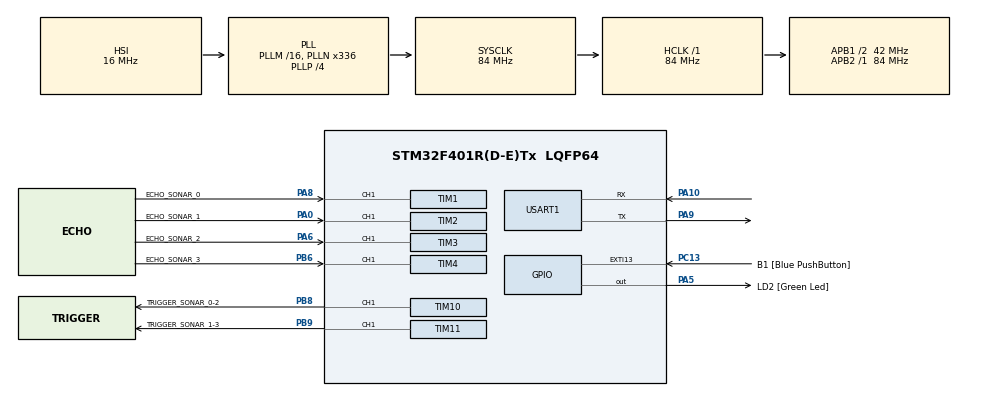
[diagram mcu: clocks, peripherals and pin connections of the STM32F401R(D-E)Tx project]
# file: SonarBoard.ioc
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Mcu.Family=STM32F4
Mcu.Name=STM32F401R(D-E)Tx
Mcu.Package=LQFP64
NVIC.PriorityGroup=NVIC_PRIORITYGROUP_4
NVIC.TIM1_CC_IRQn=true\:0\:0\:false
NVIC.TIM2_IRQn=true\:0\:0\:false
NVIC.TIM3_IRQn=true\:0\:0\:false
NVIC.TIM4_IRQn=true\:0\:0\:false
NVIC.TIM5_IRQn=true\:0\:0\:false
NVIC.USART1_IRQn=true\:0\:0\:false
PA0-WKUP.GPIO_Label=ECHO_SONAR_1
PA0-WKUP.Signal=S_TIM2_CH1_ETR
PA10.Mode=Asynchronous
PA10.Signal=USART1_RX
PA13.GPIO_Label=TMS
PA13.Mode=Trace-Asynchronous_SW
PA13.Signal=SYS_JTMS-SWDIO
PA14.GPIO_Label=TCK
PA14.Mode=Trace-Asynchronous_SW
PA14.Signal=SYS_JTCK-SWCLK
PA2.GPIO_Label=USART_TX
PA2.GPIO_Mode=GPIO_MODE_AF_PP
PA2.GPIO_PuPd=GPIO_NOPULL
PA2.GPIO_Speed=GPIO_SPEED_LOW
PA2.Signal=USART2_TX
PA3.GPIO_Label=USART_RX
PA3.GPIO_Mode=GPIO_MODE_AF_PP
PA3.GPIO_PuPd=GPIO_NOPULL
PA3.GPIO_Speed=GPIO_SPEED_LOW
PA3.Signal=USART2_RX
PA5.GPIO_Label=LD2 [Green Led]
PA5.GPIO_Mode=GPIO_MODE_OUTPUT_PP
PA5.GPIO_PuPd=GPIO_NOPULL
PA5.GPIO_Speed=GPIO_SPEED_LOW
PA5.Signal=GPIO_Output
PA6.GPIO_Label=ECHO_SONAR_2
PA6.Signal=S_TIM3_CH1
PA8.GPIO_Label=ECHO_SONAR_0
PA8.Signal=S_TIM1_CH1
PA9.Mode=Asynchronous
PA9.Signal=USART1_TX
PB3.GPIO_Label=SWO
PB3.Mode=Trace-Asynchronous_SW
PB3.Signal=SYS_JTDO-SWO
PB6.GPIO_Label=ECHO_SONAR_3
PB6.Signal=S_TIM4_CH1
PB8.GPIO_Label=TRIGGER_SONAR_0-2
PB8.Signal=S_TIM10_CH1
PB9.GPIO_Label=TRIGGER_SONAR_1-3
PB9.Signal=S_TIM11_CH1
PC13-ANTI_TAMP.GPIO_Label=B1 [Blue PushButton]
PC13-ANTI_TAMP.GPIO_ModeDefaultEXTI=GPIO_MODE_EVT_RISING
PC13-ANTI_TAMP.GPIO_PuPd=GPIO_NOPULL
PC13-ANTI_TAMP.Signal=GPXTI13
PC14-OSC32_IN.Signal=RCC_OSC32_IN
PC15-OSC32_OUT.Signal=RCC_OSC32_OUT
PH0\ -\ OSC_IN.Signal=RCC_OSC_IN
PH1\ -\ OSC_OUT.Signal=RCC_OSC_OUT
ProjectManager.TargetToolchain=EWARM
RCC.AHBFreq_Value=84000000
RCC.APB1CLKDivider=RCC_HCLK_DIV2
RCC.APB1Freq_Value=42000000
RCC.APB1TimFreq_Value=84000000
RCC.APB2Freq_Value=84000000
RCC.APB2TimFreq_Value=84000000
RCC.CortexFreq_Value=84000000
RCC.HCLKFreq_Value=84000000
RCC.HSE_VALUE=8000000
RCC.HSI_VALUE=16000000
RCC.LSE_VALUE=32768
RCC.PLLN=336
RCC.PLLP=RCC_PLLP_DIV4
RCC.PLLQ=7
RCC.SYSCLKFreq_VALUE=84000000
RCC.SYSCLKSource=RCC_SYSCLKSOURCE_PLLCLK
RCC.VCOOutputFreq_Value=336000000
SH.S_TIM10_CH1.0=TIM10_CH1,PWM Generation1 CH1
SH.S_TIM11_CH1.0=TIM11_CH1,PWM Generation1 CH1
SH.S_TIM1_CH1.0=TIM1_CH1,TriggerSource_TI1FP1
SH.S_TIM1_CH1.1=TIM1_CH1,Input_Capture1_from_TI1
SH.S_TIM1_CH1.2=TIM1_CH1,Input_Capture2_from_TI1
SH.S_TIM2_CH1_ETR.0=TIM2_CH1,TriggerSource_TI1FP1
SH.S_TIM2_CH1_ETR.1=TIM2_CH1,Input_Capture1_from_TI1
SH.S_TIM2_CH1_ETR.2=TIM2_CH1,Input_Capture2_from_TI1
SH.S_TIM3_CH1.0=TIM3_CH1,TriggerSource_TI1FP1
SH.S_TIM3_CH1.1=TIM3_CH1,Input_Capture1_from_TI1
SH.S_TIM3_CH1.2=TIM3_CH1,Input_Capture2_from_TI1
SH.S_TIM4_CH1.0=TIM4_CH1,TriggerSource_TI1FP1
SH.S_TIM4_CH1.1=TIM4_CH1,Input_Capture1_from_TI1
SH.S_TIM4_CH1.2=TIM4_CH1,Input_Capture2_from_TI1
TIM1.Channel-Input_Capture2_from_TI1=TIM_CHANNEL_2
TIM1.ICPolarity_CH2=TIM_INPUTCHANNELPOLARITY_FALLING
TIM1.Period=65535
TIM1.Prescaler=83
TIM10.OCFastMode_PWM=TIM_OCFAST_ENABLE
TIM10.OCMode_PWM=TIM_OCMODE_PWM2
TIM10.Period=65535
TIM10.Prescaler=83
TIM10.Pulse=65526
TIM11.OCFastMode_PWM=TIM_OCFAST_ENABLE
TIM11.OCMode_PWM=TIM_OCMODE_PWM2
TIM11.Period=65535
TIM11.Prescaler=83
TIM11.Pulse=65526
TIM2.Channel-Input_Capture2_from_TI1=TIM_CHANNEL_2
TIM2.ICPolarity_CH2=TIM_INPUTCHANNELPOLARITY_FALLING
TIM2.Period=65535
TIM2.Prescaler=83
TIM3.Channel-Input_Capture2_from_TI1=TIM_CHANNEL_2
TIM3.ICPolarity_CH2=TIM_INPUTCHANNELPOLARITY_FALLING
TIM3.Period=65535
TIM3.Prescaler=83
TIM4.Channel-Input_Capture2_from_TI1=TIM_CHANNEL_2
TIM4.ICPolarity_CH2=TIM_INPUTCHANNELPOLARITY_FALLING
TIM4.Period=65535
TIM4.Prescaler=83
TIM5.Period=1000
TIM5.Prescaler=8400
VP_TIM10_VS_ClockSourceINT.Mode=Enable_Timer
VP_TIM10_VS_OPM.Mode=OPM_bit
VP_TIM11_VS_ClockSourceINT.Mode=Enable_Timer
VP_TIM11_VS_OPM.Mode=OPM_bit
VP_TIM1_VS_ClockSourceINT.Mode=Internal
VP_TIM1_VS_ControllerModeReset.Mode=Reset Mode
VP_TIM2_VS_ClockSourceINT.Mode=Internal
VP_TIM2_VS_ControllerModeReset.Mode=Reset Mode
VP_TIM3_VS_ClockSourceINT.Mode=Internal
VP_TIM3_VS_ControllerModeReset.Mode=Reset Mode
VP_TIM4_VS_ClockSourceINT.Mode=Internal
VP_TIM4_VS_ControllerModeReset.Mode=Reset Mode
VP_TIM5_VS_ClockSourceINT.Mode=Internal
board=NUCLEO-F401RE

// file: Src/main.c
/**
  ******************************************************************************
  * File Name          : main.c
  * Description        : Main program body
  ******************************************************************************
  *
  * COPYRIGHT(c) 2016 STMicroelectronics
  *
  * Redistribution and use in source and binary forms, with or without modification,
  * are permitted provided that the following conditions are met:
  *   1. Redistributions of source code must retain the above copyright notice,
  *      this list of conditions and the following disclaimer.
  *   2. Redistributions in binary form must reproduce the above copyright notice,
  *      this list of conditions and the following disclaimer in the documentation
  *      and/or other materials provided with the distribution.
  *   3. Neither the name of STMicroelectronics nor the names of its contributors
  *      may be used to endorse or promote products derived from this software
  *      without specific prior written permission.
  *
  * THIS SOFTWARE IS PROVIDED BY THE COPYRIGHT HOLDERS AND CONTRIBUTORS "AS IS"
  * AND ANY EXPRESS OR IMPLIED WARRANTIES, INCLUDING, BUT NOT LIMITED TO, THE
  * IMPLIED WARRANTIES OF MERCHANTABILITY AND FITNESS FOR A PARTICULAR PURPOSE ARE
  * DISCLAIMED. IN NO EVENT SHALL THE COPYRIGHT HOLDER OR CONTRIBUTORS BE LIABLE
  * FOR ANY DIRECT, INDIRECT, INCIDENTAL, SPECIAL, EXEMPLARY, OR CONSEQUENTIAL
  * DAMAGES (INCLUDING, BUT NOT LIMITED TO, PROCUREMENT OF SUBSTITUTE GOODS OR
  * SERVICES; LOSS OF USE, DATA, OR PROFITS; OR BUSINESS INTERRUPTION) HOWEVER
  * CAUSED AND ON ANY THEORY OF LIABILITY, WHETHER IN CONTRACT, STRICT LIABILITY,
  * OR TORT (INCLUDING NEGLIGENCE OR OTHERWISE) ARISING IN ANY WAY OUT OF THE USE
  * OF THIS SOFTWARE, EVEN IF ADVISED OF THE POSSIBILITY OF SUCH DAMAGE.
  *
  ******************************************************************************
  */
#include "stm32f4xx_hal.h"
#include "tim.h"
#include "usart.h"
#include "gpio.h"

/* USER CODE BEGIN Includes */
#include "sonar_handler.h"
#include "ser_handler.h"
#include "gpio.h"
/* USER CODE END Includes */

/* USER CODE BEGIN PV */
/* Private variables ---------------------------------------------------------*/

/* USER CODE END PV */

void SystemClock_Config(void);

/* USER CODE BEGIN PFP */
/* Private function prototypes -----------------------------------------------*/

/* USER CODE END PFP */

int main(void)
{

  /* USER CODE BEGIN 1 */f

  /* USER CODE END 1 */

  /* MCU Configuration----------------------------------------------------------*/

  /* Reset of all peripherals, Initializes the Flash interface and the Systick. */
  HAL_Init();

  /* Configure the system clock */
  SystemClock_Config();

  /* Initialize all configured peripherals */
  MX_GPIO_Init();
  MX_TIM1_Init();
  MX_TIM2_Init();
  MX_TIM3_Init();
  MX_TIM4_Init();
  MX_TIM5_Init();
  MX_TIM10_Init();
  MX_TIM11_Init();
  MX_USART1_UART_Init();

  /* USER CODE BEGIN 2 */
  HAL_TIM_Base_Start_IT( &htim5 ); // 100 msec timer
  initSonar( 4 );
  initSerOutput();
  /* USER CODE END 2 */

  /* Infinite loop */
  while (1)
  {

  /* USER CODE BEGIN 3 */
    // >>>>> Sonar reading
    triggerSonar( COUPLE_0_2 );
    HAL_Delay( 50 ); // 38 msec is the max echo duration
    triggerSonar( COUPLE_1_3 );
    HAL_Delay( 50 ); // 38 msec is the max echo duration
    // <<<<< Sonar reading

    // >>>>> Serial Output
    sendMeasures();
    // <<<<< Serial Output
  }
  /* USER CODE END 3 */

}

/** System Clock Configuration
*/
void SystemClock_Config(void)
{

  RCC_OscInitTypeDef RCC_OscInitStruct;
  RCC_ClkInitTypeDef RCC_ClkInitStruct;

  __PWR_CLK_ENABLE();

  __HAL_PWR_VOLTAGESCALING_CONFIG(PWR_REGULATOR_VOLTAGE_SCALE2);

  RCC_OscInitStruct.OscillatorType = RCC_OSCILLATORTYPE_HSI;
  RCC_OscInitStruct.HSIState = RCC_HSI_ON;
  RCC_OscInitStruct.HSICalibrationValue = 16;
  RCC_OscInitStruct.PLL.PLLState = RCC_PLL_ON;
  RCC_OscInitStruct.PLL.PLLSource = RCC_PLLSOURCE_HSI;
  RCC_OscInitStruct.PLL.PLLM = 16;
  RCC_OscInitStruct.PLL.PLLN = 336;
  RCC_OscInitStruct.PLL.PLLP = RCC_PLLP_DIV4;
  RCC_OscInitStruct.PLL.PLLQ = 7;
  HAL_RCC_OscConfig(&RCC_OscInitStruct);

  RCC_ClkInitStruct.ClockType = RCC_CLOCKTYPE_SYSCLK|RCC_CLOCKTYPE_PCLK1;
  RCC_ClkInitStruct.SYSCLKSource = RCC_SYSCLKSOURCE_PLLCLK;
  RCC_ClkInitStruct.AHBCLKDivider = RCC_SYSCLK_DIV1;
  RCC_ClkInitStruct.APB1CLKDivider = RCC_HCLK_DIV2;
  RCC_ClkInitStruct.APB2CLKDivider = RCC_HCLK_DIV1;
  HAL_RCC_ClockConfig(&RCC_ClkInitStruct, FLASH_LATENCY_2);

  HAL_SYSTICK_Config(HAL_RCC_GetHCLKFreq()/1000);

  HAL_SYSTICK_CLKSourceConfig(SYSTICK_CLKSOURCE_HCLK);

  /* SysTick_IRQn interrupt configuration */
  HAL_NVIC_SetPriority(SysTick_IRQn, 0, 0);
}

/************************ (C) COPYRIGHT STMicroelectronics *****END OF FILE****/
